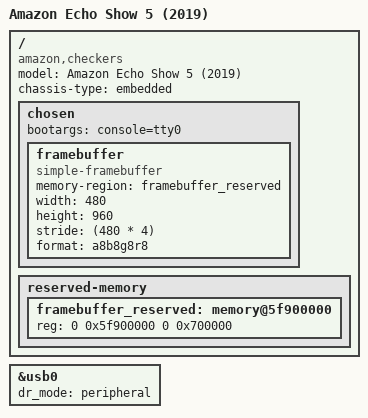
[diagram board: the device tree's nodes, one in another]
// SPDX-License-Identifier: GPL-2.0-only OR MIT
/*
 * Copyright (c) 2025-2026 Ben Grisdale <bengris32@protonmail.ch>
 * Copyright (c) 2025-2026 Jack Matthews <jack@jackmatthe.ws>
 */

#include "mt8163-amazon-show.dtsi"

/ {
	model = "Amazon Echo Show 5 (2019)";
	compatible = "amazon,checkers", "mediatek,mt8163";
	chassis-type = "embedded";

	chosen {
		bootargs = "console=tty0";

		framebuffer {
			compatible = "simple-framebuffer";
			memory-region = <&framebuffer_reserved>;
			width = <480>;
			height = <960>;
			stride = <(480 * 4)>;
			format = "a8b8g8r8";

			status = "okay";
		};
	};

	reserved-memory {
		#address-cells = <2>;
		#size-cells = <2>;

		ranges;

		framebuffer_reserved: memory@5f900000 {
			reg = <0 0x5f900000 0 0x700000>;
		};
	};
};

&usb0 {
	/* No 5V supply for OTG support. */
	dr_mode = "peripheral";
	status = "okay";
};
